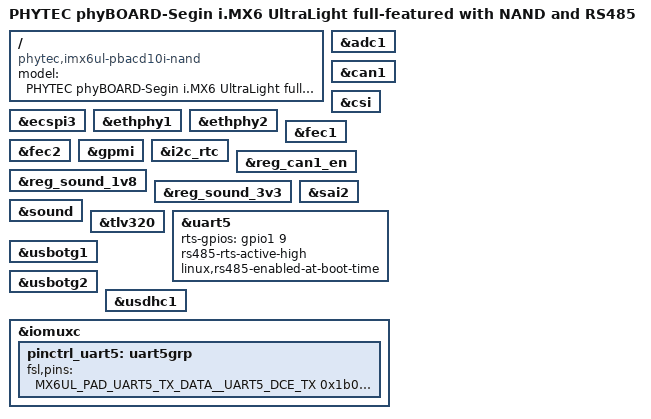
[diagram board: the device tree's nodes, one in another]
// SPDX-License-Identifier: (GPL-2.0+ OR MIT)
/*
 * Copyright (C) 2017 PHYTEC Messtechnik GmbH
 * Author: Stefan Riedmüller <s.riedmueller@phytec.de>
 */

/dts-v1/;
#include "imx6ul.dtsi"
#include "imx6ul-phytec-phycore-som.dtsi"
#include "imx6ul-phytec-segin.dtsi"
#include "imx6ul-phytec-segin-peb-av-02.dtsi"
#include "imx6ul-phytec-segin-peb-eval-01.dtsi"
#include "imx6ul-phytec-segin-phycam.dtsi"
#include "imx6ul-phytec-segin-peb-wlbt-05.dtsi"

/ {
	model = "PHYTEC phyBOARD-Segin i.MX6 UltraLight full-featured with NAND and RS485";
	compatible = "phytec,imx6ul-pbacd10i-nand", "phytec,imx6ul-pbacd10",
		     "phytec,imx6ul-pcl063", "fsl,imx6ul";
};

&adc1 {
	status = "okay";
};

&can1 {
	status = "okay";
};

&csi {
	status = "okay";
};

&ecspi3 {
	status = "okay";
};

&ethphy1 {
	status = "okay";
};

&ethphy2 {
	status = "okay";
};

&fec1 {
	status = "okay";
};

&fec2 {
	status = "okay";
};

&gpmi {
	status = "okay";
};

&i2c_rtc {
	status = "okay";
};

&reg_can1_en {
	status = "okay";
};

&reg_sound_1v8 {
	status = "okay";
};

&reg_sound_3v3 {
	status = "okay";
};

&sai2 {
	status = "okay";
};

&sound {
	status = "okay";
};

&tlv320 {
	status = "okay";
};

&uart5 {
	rts-gpios = <&gpio1 9 GPIO_ACTIVE_HIGH>;
	rs485-rts-active-high;
	linux,rs485-enabled-at-boot-time;
	status = "okay";
};

&usbotg1 {
	status = "okay";
};

&usbotg2 {
	status = "okay";
};

&usdhc1 {
	status = "okay";
};

&iomuxc {
	pinctrl_uart5: uart5grp {
		fsl,pins = <
			MX6UL_PAD_UART5_TX_DATA__UART5_DCE_TX	0x1b0b1
			MX6UL_PAD_UART5_RX_DATA__UART5_DCE_RX	0x1b0b1
			MX6UL_PAD_GPIO1_IO09__GPIO1_IO09	0x1a0b1
		>;
	};
};
